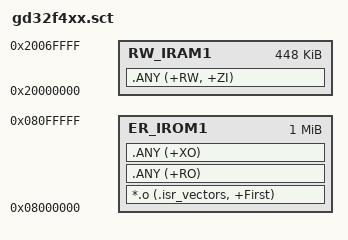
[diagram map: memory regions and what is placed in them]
; *************************************************************
; *** Scatter-Loading Description File generated by uVision ***
; *************************************************************

LR_IROM1 0x08000000 0x00100000  {    ; load region size_region
    ; 根据gd32f470zg官方手册，RAM空间为1M
    ER_IROM1 0x08000000 0x00100000  {  ; load address = execution address
        *.o (.isr_vectors, +First)
        .ANY (+RO)
        .ANY (+XO)
    }

    ; 根据gd32f470zg官方手册，RAM空间为448K
    RW_IRAM1 0x20000000 0x00070000  {  ; RW data
        .ANY (+RW, +ZI)
    }

;   ; 栈空间
;   ARM_LIB_STACK 0x2006F800 EMPTY -0x800 {
;   }
;
;   ; 堆空间
;   ARM_LIB_HEAP +0 EMPTY 0x800 {
;   }
}

